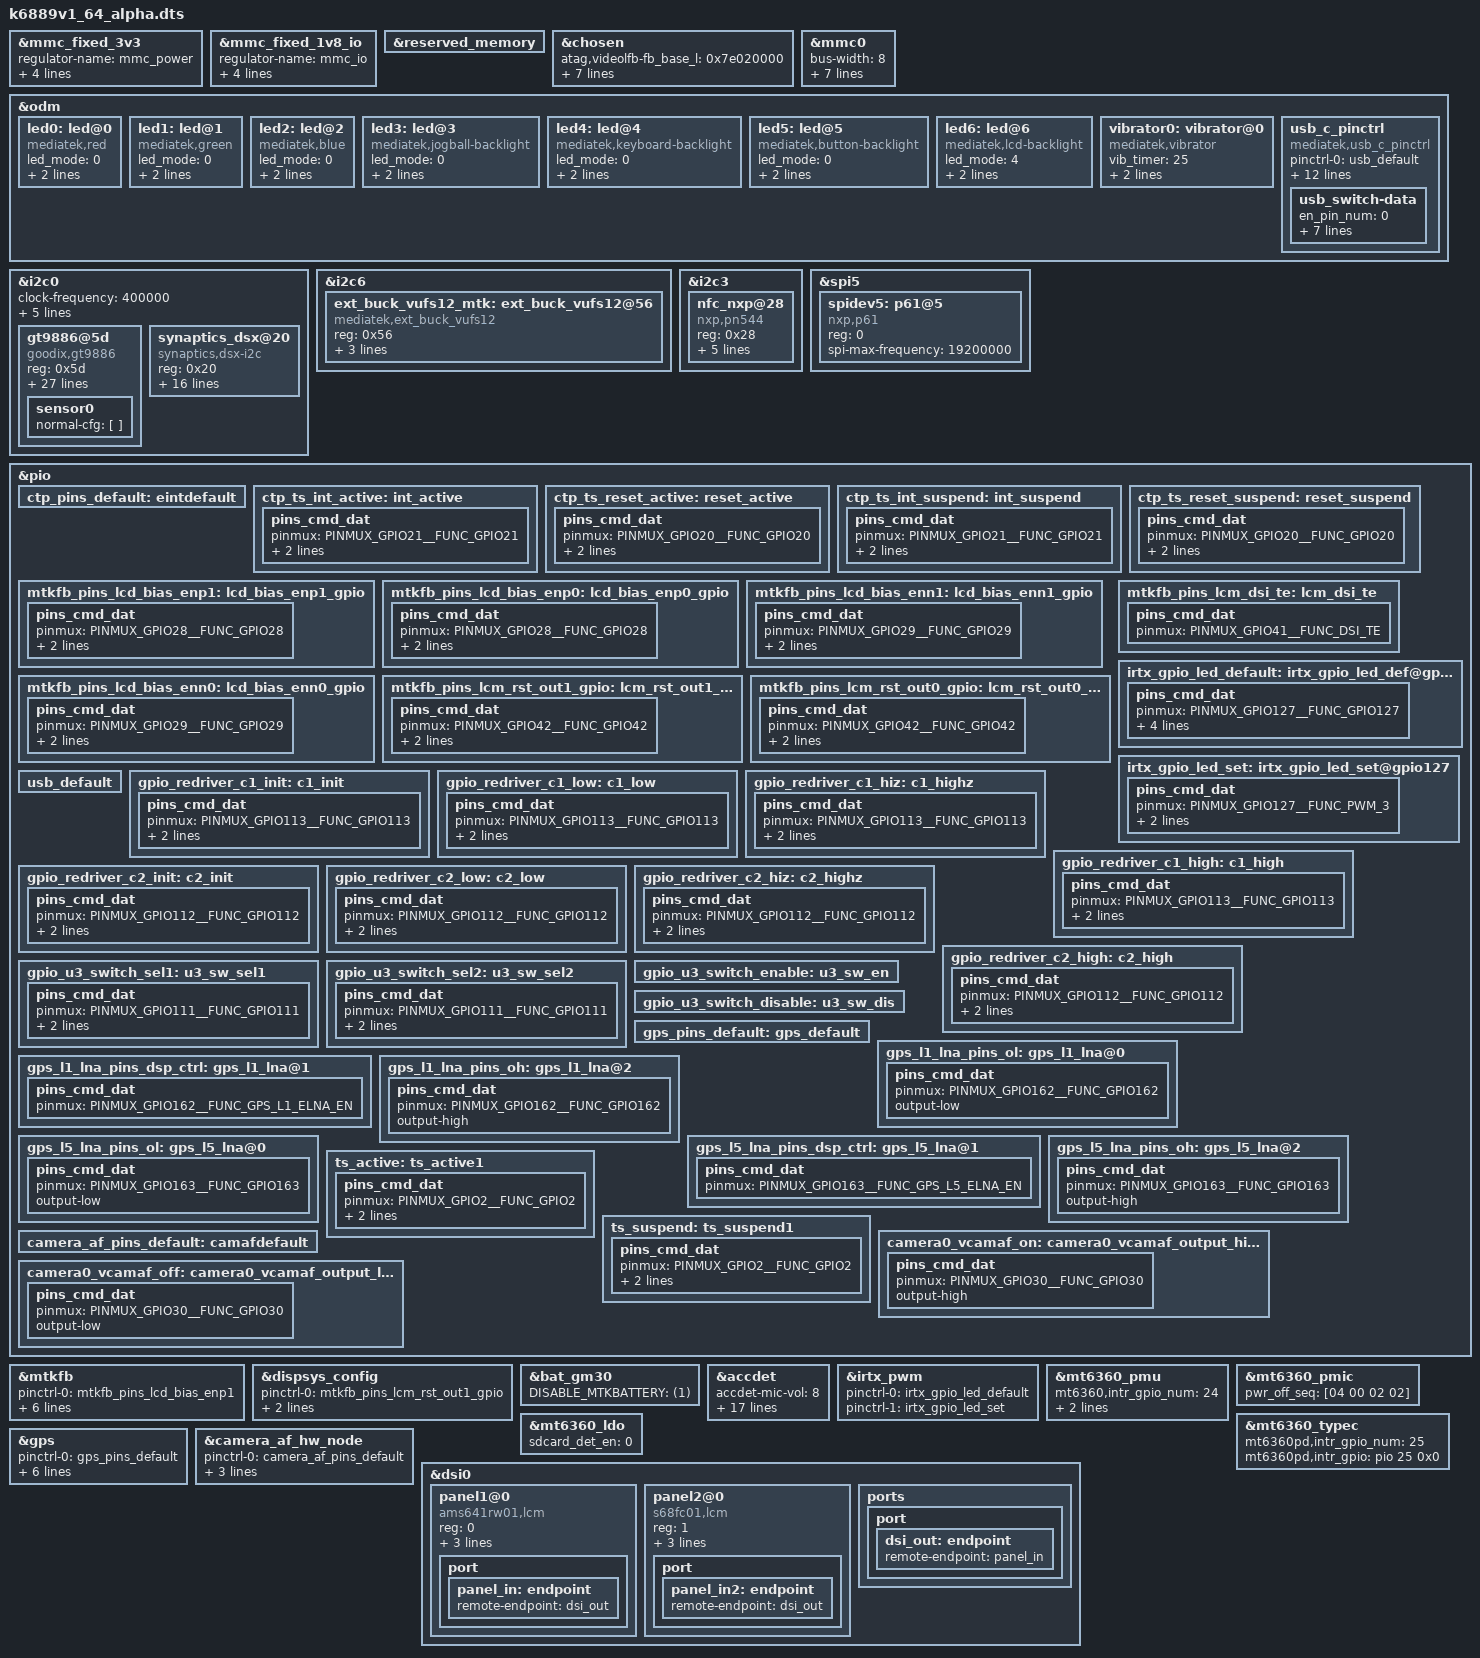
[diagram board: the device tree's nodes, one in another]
/*
 * Mediatek's mt6885 SoC device tree source
 *
 * Copyright (C) 2016 MediaTek Inc.
 *
 * This program is free software; you can redistribute it and/or modify
 * it under the terms of the GNU General Public License version 2 as
 * published by the Free Software Foundation.
 *
 * This program is distributed in the hope that it will be useful,
 * but WITHOUT ANY WARRANTY; without even the implied warranty of
 * MERCHANTABILITY or FITNESS FOR A PARTICULAR PURPOSE.
 * See http://www.gnu.org/licenses/gpl-2.0.html for more details.
 */
/dts-v1/;
/plugin/;
#include <dt-bindings/interrupt-controller/irq.h>
#include <dt-bindings/interrupt-controller/arm-gic.h>
#include <dt-bindings/spmi/spmi.h>
#include <dt-bindings/pinctrl/mt6885-pinfunc.h>

&mmc_fixed_3v3 {
	status = "okay";
	regulator-name = "mmc_power";
	regulator-min-microvolt = <3300000>;
	regulator-max-microvolt = <3300000>;
	enable-active-high;
	regulator-always-on;
};

&mmc_fixed_1v8_io {
	status = "okay";
	regulator-name = "mmc_io";
	regulator-min-microvolt = <1800000>;
	regulator-max-microvolt = <1800000>;
	enable-active-high;
	regulator-always-on;
};

&reserved_memory {
};

/* chosen */
&chosen {

	atag,videolfb-fb_base_l = <0x7e020000>;
	atag,videolfb-fb_base_h = <0x0>;
	atag,videolfb-islcmfound = <1>;
	atag,videolfb-islcm_inited = <0>;
	atag,videolfb-fps= <6000>;
	atag,videolfb-vramSize= <0x1be0000>;
	atag,videolfb-lcmname=
		"nt35595_fhd_dsi_cmd_truly_nt50358_drv";
};

&mmc0 {
	status = "okay";
	/* pinctrl-names = "default", "state_uhs"; */
	/* pinctrl-0 = <&mmc0_pins_default>; */
	/* pinctrl-1 = <&mmc0_pins_uhs>; */
	bus-width = <8>;
	max-frequency = <5000000>;
	cap-mmc-highspeed;
	no-sdio;
	no-sd;
	vmmc-supply = <&mmc_fixed_3v3>;
	vqmmc-supply = <&mmc_fixed_1v8_io>;
	non-removable;
};

&odm {
	led0:led@0 {
		compatible = "mediatek,red";
		led_mode = <0>;
		data = <1>;
		pwm_config = <0 0 0 0 0>;
	};
	led1:led@1 {
		compatible = "mediatek,green";
		led_mode = <0>;
		data = <1>;
		pwm_config = <0 0 0 0 0>;
	};
	led2:led@2 {
		compatible = "mediatek,blue";
		led_mode = <0>;
		data = <1>;
		pwm_config = <0 0 0 0 0>;
	};
	led3:led@3 {
		compatible = "mediatek,jogball-backlight";
		led_mode = <0>;
		data = <1>;
		pwm_config = <0 0 0 0 0>;
	};
	led4:led@4 {
		compatible = "mediatek,keyboard-backlight";
		led_mode = <0>;
		data = <1>;
		pwm_config = <0 0 0 0 0>;
	};
	led5:led@5 {
		compatible = "mediatek,button-backlight";
		led_mode = <0>;
		data = <1>;
		pwm_config = <0 0 0 0 0>;
	};
	led6:led@6 {
		compatible = "mediatek,lcd-backlight";
		led_mode = <4>;
		data = <1>;
		pwm_config = <0 1 0 0 0>;
	};
	vibrator0:vibrator@0 {
		compatible = "mediatek,vibrator";
		vib_timer = <25>;
		vib_limit = <9>;
		vib_vol= <9>;
	};
	usb_c_pinctrl:usb_c_pinctrl {
		compatible = "mediatek,usb_c_pinctrl";
	};
};

/* TOUCH start */
&i2c0 {
	clock-frequency = <400000>;
	pinctrl-names = "default", "ts_int_active",
		"ts_reset_active", "ts_int_suspend", "ts_reset_suspend";
	pinctrl-0 = <&ctp_pins_default>;
	pinctrl-1 = <&ctp_ts_int_active>;
	pinctrl-2 = <&ctp_ts_reset_active>;
	pinctrl-3 = <&ctp_ts_int_suspend>;
	pinctrl-4 = <&ctp_ts_reset_suspend>;

	gt9886@5d {
		compatible = "goodix,gt9886";
		reg = <0x5d>;
		status = "ok";
		interrupt-parent = <&pio>;
		interrupts = <21 IRQ_TYPE_EDGE_FALLING 21 0>;
		vtouch-supply = <&mt_pmic_vtp_ldo_reg>;
		goodix,reset-gpio = <&pio 20 0x0>;
		goodix,irq-gpio = <&pio 21 0x0>;
		goodix,irq-flags = <2>; /* 1:rising, 2:falling;*/
		goodix,panel-max-id = <10>;
		goodix,panel-max-x = <1080>;
		goodix,panel-max-y = <2400>;
		goodix,panel-max-w = <256>;
		goodix,panel-max-p = <256>;
		goodix,input-max-x = <1080>;
		goodix,input-max-y = <2400>;
		goodix,panel-key-map = <158 172 217>; /*BACK,HOMEPAGE,SEARCH*/
		goodix,power-on-delay-us = <10000>; /*10ms*/
		goodix,power-off-delay-us = <5000>;
		goodix,firmware-version = "6885b0";
		goodix,config-version = "gt9885v1";
		/*goodix,swap-axis;*/
		goodix,x2x;
		goodix,y2y;
		goodix,pen-enable;
		goodix,key-of-pen = <331 332>;/*BTN_STYLUS, BTN_STYLUS2*/
		tpd-filter-enable = <0>;
		tpd-filter-pixel-density = <168>;
		tpd-filter-custom-prameters = <0 0 0 0 0 0 0 0 0 0 0 0>;
		tpd-filter-custom-speed = <0 0 0>;
		sensor0 {
			normal-cfg = [
			];
		};
	};

};

&i2c6 {
	ext_buck_vufs12_mtk:ext_buck_vufs12@56 {
		compatible = "mediatek,ext_buck_vufs12";
		reg = <0x56>;
		regulator-name = "ext_buck_vufs12";
		regulator-min-microvolt = <300000>;
		regulator-max-microvolt = <1300000>;
		status = "okay";
	};
};
&i2c3 {
       status = "okay";
       nfc_nxp@28 {
               compatible = "nxp,pn544";
               reg = <0x28>;
               nxp,pn544-irq = <&pio 7 0x0>;
               nxp,pn544-ven = <&pio 16 0x0>;
               nxp,pn544-fw-dwnld = <&pio 6 0x0>;
               nxp,pn544-clkreq = <&pio 17 0x0>;
               interrupt-parent = <&pio>;
       };
};

&spi5 {
       status = "okay";
       #address-cells = <1>;
       #size-cells = <0>;
       spidev5: p61@5 {
       compatible = "nxp,p61";
       reg = <0>;
       spi-max-frequency = <19200000>;
       };
};

&pio {
	ctp_pins_default: eintdefault {
	};
	ctp_ts_int_active: int_active {
		pins_cmd_dat {
			pinmux = <PINMUX_GPIO21__FUNC_GPIO21>;
			slew-rate = <0>;
			bias-pull-up = <11>;
		};
	};
	ctp_ts_reset_active: reset_active {
		pins_cmd_dat {
			pinmux = <PINMUX_GPIO20__FUNC_GPIO20>;
			slew-rate = <1>;
			output-high;
		};
	};
	ctp_ts_int_suspend: int_suspend {
		pins_cmd_dat {
			pinmux = <PINMUX_GPIO21__FUNC_GPIO21>;
			slew-rate = <1>;
			output-low;
		};
	};
	ctp_ts_reset_suspend: reset_suspend {
		pins_cmd_dat {
			pinmux = <PINMUX_GPIO20__FUNC_GPIO20>;
			slew-rate = <1>;
			output-low;
		};
	};
};
/* TOUCH end */

/* DISPSYS GPIO standardization */
&pio {
	mtkfb_pins_lcd_bias_enp1: lcd_bias_enp1_gpio {
		pins_cmd_dat {
			pinmux = <PINMUX_GPIO28__FUNC_GPIO28>;
			slew-rate = <1>;
			output-high;
		};
	};

	mtkfb_pins_lcd_bias_enp0: lcd_bias_enp0_gpio {
		pins_cmd_dat {
			pinmux = <PINMUX_GPIO28__FUNC_GPIO28>;
			slew-rate = <1>;
			output-low;
		};
	};

	mtkfb_pins_lcd_bias_enn1: lcd_bias_enn1_gpio {
		pins_cmd_dat {
			pinmux = <PINMUX_GPIO29__FUNC_GPIO29>;
			slew-rate = <1>;
			output-high;
		};
	};

	mtkfb_pins_lcd_bias_enn0: lcd_bias_enn0_gpio {
		pins_cmd_dat {
			pinmux = <PINMUX_GPIO29__FUNC_GPIO29>;
			slew-rate = <1>;
			output-low;
		};
	};

	mtkfb_pins_lcm_rst_out1_gpio: lcm_rst_out1_gpio {
		pins_cmd_dat {
			pinmux = <PINMUX_GPIO42__FUNC_GPIO42>;
			slew-rate = <1>;
			output-high;
		};
	};

	mtkfb_pins_lcm_rst_out0_gpio: lcm_rst_out0_gpio {
		pins_cmd_dat {
			pinmux = <PINMUX_GPIO42__FUNC_GPIO42>;
			slew-rate = <1>;
			output-low;
		};
	};

	mtkfb_pins_lcm_dsi_te: lcm_dsi_te {
		pins_cmd_dat {
			pinmux = <PINMUX_GPIO41__FUNC_DSI_TE>;
		};
	};
};

&mtkfb {
	pinctrl-names = "lcd_bias_enp1_gpio", "lcd_bias_enp0_gpio",
		"lcd_bias_enn1_gpio", "lcd_bias_enn0_gpio",
		"lcm_rst_out1_gpio", "lcm_rst_out0_gpio",
		"mode_te_te";
	pinctrl-0 = <&mtkfb_pins_lcd_bias_enp1>;
	pinctrl-1 = <&mtkfb_pins_lcd_bias_enp0>;
	pinctrl-2 = <&mtkfb_pins_lcd_bias_enn1>;
	pinctrl-3 = <&mtkfb_pins_lcd_bias_enn0>;
	pinctrl-4 = <&mtkfb_pins_lcm_rst_out1_gpio>;
	pinctrl-5 = <&mtkfb_pins_lcm_rst_out0_gpio>;
	pinctrl-6 = <&mtkfb_pins_lcm_dsi_te>;
	status = "okay";
};

&dispsys_config {
	pinctrl-names =
		"lcm_rst_out1_gpio", "lcm_rst_out0_gpio",
		"mode_te_te";
	pinctrl-0 = <&mtkfb_pins_lcm_rst_out1_gpio>;
	pinctrl-1 = <&mtkfb_pins_lcm_rst_out0_gpio>;
	pinctrl-2 = <&mtkfb_pins_lcm_dsi_te>;
	status = "okay";
};

&bat_gm30 {
	DISABLE_MTKBATTERY = <(1)>;
};

/* DISPSYS GPIO standardization end */

/* accdet start */
&accdet {
	/* accdet micbias voltage: 0x09:2.85v 0x08:2.8v 0x07,
	 * 2.7v;0x05,2.5v;0x02,1.9v
	 */
	accdet-mic-vol = <8>;
	/* accdet pwm_width, pwm_thresh, fall_delay, rise_delay
	 * debounce0, debounce1, debounce3, debounce4
	 * eint pwm_width, eint pwm_thresh
	 * eint deb(debounce0, debounce1, debounce2, debounce3), inv_debounce
	 */
	headset-mode-setting = <0x500 0x500 1 0x1f0
				0x2000 0x800 0x2000 0x44
				0x0 0x7
				0x5 0x9 0x9 0xd 0xe>;
	accdet-plugout-debounce = <1>;
	/*1:ACC mode, 2:low cost without in bias, 6:low cost with in bias*/
	accdet-mic-mode = <2>;
	/*0--MD_MAX--UP_MAX--DW_MAX*/
	headset-three-key-threshold = <0 80 220 400>;
	headset-three-key-threshold-CDD = <0 121 192 600>;
	/*0--MD_MAX--VOICE_MAX--UP_MAX--DW_MAX*/
	headset-four-key-threshold = <0 58 121 192 400>;

	/* moisture HW mode config start. Enable moisture detection or not
	 * default use HW mode for moisture detection
	 */
	moisture_detect_enable = <1>;
	/* select VTH to 2v and 500k, use internal resitance */
	eint_use_ext_res = <0>;
	/* enable eint detection mode, if moisture detection enable
	 * eint_detect_mode = moisture_detect_mode;otherwise, select
	 * eint_detect_mode = 4 as DEFAULT
	 */
	eint_detect_mode = <5>;
	/* enable moisture detection mode, if moisture detection enable
	 * eint_detect_mode = moisture_detect_mode
	 */
	moisture_detect_mode = <5>;
	/* select 0: 2.8V; 1: 2.4V; 2: 2V; 3: VTH=MVTH(VTH2) */
	moisture_comp_vth = <2>;
	/* vref2 voltage for different water impedance */
	moisture_comp_vref2 = <0>;
	/* moisture HW mode config end */

	/* moisture SW mode config start, use external resister or not.
	 * DEFAULT NOT NEED
	 */
	moisture_use_ext_res = <0>;
	/* moisture external resister ohm, SW mode by auxadc */
	moisture-external-r = <2000000>;
	/* moisture internal resister ohm, SW mode by auxadc */
	moisture-internal-r = <47000>;
	/* moisture of water resister ohm, SW mode by auxadc*/
	moisture-water-r = <10000>;
	/* moisture SW mode config end */
	status = "okay";
};
/* accdet end */

/* IRTX GPIO Start */
&irtx_pwm {
	pinctrl-names = "irtx_gpio_led_default", "irtx_gpio_led_set";
	pinctrl-0 = <&irtx_gpio_led_default>;
	pinctrl-1 = <&irtx_gpio_led_set>;
	status = "okay";
};
&pio {
	/* IRTX GPIO Settings -Start */
	/* default: GPIO0, output, high */
	irtx_gpio_led_default:irtx_gpio_led_def@gpio127 {
		pins_cmd_dat {
			pinmux = <PINMUX_GPIO127__FUNC_GPIO127>;
			slew-rate = <1>;
			bias-disable;
			output-low;
			input-schmitt-enable = <0>;
		};
	};

	irtx_gpio_led_set:irtx_gpio_led_set@gpio127 {
		pins_cmd_dat {
			pinmux = <PINMUX_GPIO127__FUNC_PWM_3>;
			slew-rate = <1>;
			output-high;
		};
	};
}; /* IRTX GPIO Settings -End */

&mt6360_pmu {
	mt6360,intr_gpio_num = <24>; /* direct defined GPIO num */
	mt6360,intr_gpio = <&pio 24 0x0>;
	disable_lpsd = <1>;
};

&mt6360_pmic {
	pwr_off_seq = [04 00 02 02];
};

&mt6360_typec {
	mt6360pd,intr_gpio_num = <25>; /* direct defined GPIO num */
	mt6360pd,intr_gpio = <&pio 25 0x0>;
};

&mt6360_ldo {
	sdcard_det_en = <0>;
};

/* USB SWITCH GPIO start */
&pio {
	usb_default: usb_default {
	};

	gpio_redriver_c1_init: c1_init {
		pins_cmd_dat {
			pinmux = <PINMUX_GPIO113__FUNC_GPIO113>;
			slew-rate = <1>;
			output-low;
		};
	};

	gpio_redriver_c1_low: c1_low {
		pins_cmd_dat {
			pinmux = <PINMUX_GPIO113__FUNC_GPIO113>;
			slew-rate = <1>;
			output-low;
		};
	};

	gpio_redriver_c1_hiz: c1_highz {
		pins_cmd_dat {
			pinmux = <PINMUX_GPIO113__FUNC_GPIO113>;
			slew-rate= <0>;
			bias-disable;
		};
	};

	gpio_redriver_c1_high: c1_high {
		pins_cmd_dat {
			pinmux = <PINMUX_GPIO113__FUNC_GPIO113>;
			slew-rate = <1>;
			output-high;
		};
	};

	gpio_redriver_c2_init: c2_init {
		pins_cmd_dat {
			pinmux = <PINMUX_GPIO112__FUNC_GPIO112>;
			slew-rate = <1>;
			output-low;
		};
	};

	gpio_redriver_c2_low: c2_low {
		pins_cmd_dat {
			pinmux = <PINMUX_GPIO112__FUNC_GPIO112>;
			slew-rate = <1>;
			output-low;
		};
	};

	gpio_redriver_c2_hiz: c2_highz {
		pins_cmd_dat {
			pinmux = <PINMUX_GPIO112__FUNC_GPIO112>;
			slew-rate= <0>;
			bias-disable;
		};
	};

	gpio_redriver_c2_high: c2_high {
		pins_cmd_dat {
			pinmux = <PINMUX_GPIO112__FUNC_GPIO112>;
			slew-rate = <1>;
			output-high;
		};
	};

	gpio_u3_switch_sel1: u3_sw_sel1 {
		pins_cmd_dat {
			pinmux = <PINMUX_GPIO111__FUNC_GPIO111>;
			slew-rate = <1>;
			output-low;
		};
	};

	gpio_u3_switch_sel2: u3_sw_sel2 {
		pins_cmd_dat {
			pinmux = <PINMUX_GPIO111__FUNC_GPIO111>;
			slew-rate = <1>;
			output-high;
		};
	};

	gpio_u3_switch_enable: u3_sw_en {
	};

	gpio_u3_switch_disable: u3_sw_dis {
	};
};

&usb_c_pinctrl {
	pinctrl-names = "usb_default",
		"redrv_c1_init",
		"redrv_c1_low",
		"redrv_c1_hiz",
		"redrv_c1_high",
		"redrv_c2_init",
		"redrv_c2_low",
		"redrv_c2_hiz",
		"redrv_c2_high",
		"switch_sel1",
		"switch_sel2",
		"switch_enable",
		"switch_disable";

	pinctrl-0 = <&usb_default>;
	pinctrl-1 = <&gpio_redriver_c1_init>;
	pinctrl-2 = <&gpio_redriver_c1_low>;
	pinctrl-3 = <&gpio_redriver_c1_hiz>;
	pinctrl-4 = <&gpio_redriver_c1_high>;
	pinctrl-5 = <&gpio_redriver_c2_init>;
	pinctrl-6 = <&gpio_redriver_c2_low>;
	pinctrl-7 = <&gpio_redriver_c2_hiz>;
	pinctrl-8 = <&gpio_redriver_c2_high>;
	pinctrl-9 = <&gpio_u3_switch_sel1>;
	pinctrl-10 = <&gpio_u3_switch_sel2>;
	pinctrl-11 = <&gpio_u3_switch_enable>;
	pinctrl-12 = <&gpio_u3_switch_disable>;
	status = "okay";

	usb_switch-data {
		en_pin_num = <0>;
		en_pin_val = <0>;
		sel_pin_num = <111>;
		sel_pin_val = <1>;
		c1_pin_num = <113>;
		c1_pin_val = <2>;
		c2_pin_num = <112>;
		c2_pin_val = <1>;
	};
};
/* USB SWITCH GPIO end */

/* GPS GPIO standardization start */
&pio {
	gps_pins_default: gps_default {
	};

	gps_l1_lna_pins_ol: gps_l1_lna@0 {
		pins_cmd_dat {
			pinmux = <PINMUX_GPIO162__FUNC_GPIO162>;
			output-low;
		};
	};
	gps_l1_lna_pins_dsp_ctrl: gps_l1_lna@1 {
		pins_cmd_dat {
			pinmux = <PINMUX_GPIO162__FUNC_GPS_L1_ELNA_EN>;
		};
	};
	gps_l1_lna_pins_oh: gps_l1_lna@2 {
		pins_cmd_dat {
			pinmux = <PINMUX_GPIO162__FUNC_GPIO162>;
			output-high;
		};
	};

	gps_l5_lna_pins_ol: gps_l5_lna@0 {
		pins_cmd_dat {
			pinmux = <PINMUX_GPIO163__FUNC_GPIO163>;
			output-low;
		};
	};
	gps_l5_lna_pins_dsp_ctrl: gps_l5_lna@1 {
		pins_cmd_dat {
			pinmux = <PINMUX_GPIO163__FUNC_GPS_L5_ELNA_EN>;
		};
	};
	gps_l5_lna_pins_oh: gps_l5_lna@2 {
		pins_cmd_dat {
			pinmux = <PINMUX_GPIO163__FUNC_GPIO163>;
			output-high;
		};
	};
};

&gps {
	pinctrl-names = "default",
		"gps_l1_lna_disable",
		"gps_l1_lna_dsp_ctrl",
		"gps_l1_lna_enable",
		"gps_l5_lna_disable",
		"gps_l5_lna_dsp_ctrl",
		"gps_l5_lna_enable";
	pinctrl-0 = <&gps_pins_default>;
	pinctrl-1 = <&gps_l1_lna_pins_ol>;
	pinctrl-2 = <&gps_l1_lna_pins_dsp_ctrl>;
	pinctrl-3 = <&gps_l1_lna_pins_oh>;
	pinctrl-4 = <&gps_l5_lna_pins_ol>;
	pinctrl-5 = <&gps_l5_lna_pins_dsp_ctrl>;
	pinctrl-6 = <&gps_l5_lna_pins_oh>;
	status = "okay";
};
/* GPS GPIO standardization end */

&i2c0 {
	status = "ok";
	synaptics_dsx@20 {
		compatible = "synaptics,dsx-i2c";
		reg = <0x20>;
		interrupt-parent = <&pio>;
		interrupts = <1 0x2008>;
		vdd-supply = <&mt_pmic_vtp_ldo_reg>;
		avdd-supply = <&mt_pmic_vtp_ldo_reg>;
		pinctrl-names = "pmx_ts_active", "pmx_ts_suspend";
		pinctrl-0 = <&ts_active>;
		pinctrl-1 = <&ts_suspend>;
		synaptics,pwr-reg-name = "avdd";
		synaptics,bus-reg-name = "vdd";
		synaptics,ub-i2c-addr = <0x2c>;
		synaptics,reset-gpio = <&pio 20 0>;
		synaptics,irq-gpio = <&pio 21 0x2008>; /* IRQF_ONESHOT | IRQF_TRIGGER_LOW */
		synaptics,irq-on-state = <0>;
		synaptics,power-delay-ms = <8>;
		synaptics,reset-delay-ms = <90>;
		synaptics,reset-on-state = <0>;
		synaptics,reset-active-ms = <2>;
		/* uncomment and update line below as appropriate if there are 0D buttons */
		/* synaptics,cap-button-codes = <102 158>; */
		/* uncomment and update lines below as appropriate if there are virtual buttons */
		/* synaptics,vir-button-codes = <102 100 900 100 60 158 300 900 100 60>; */
		/* synaptics,max-y-for-2d = <800>; */
	};
};

&pio {
	ts_active: ts_active1 {
		pins_cmd_dat {
			pinmux = <PINMUX_GPIO2__FUNC_GPIO2>;
			slew-rate = <1>;
			output-high;
		};
	};
	ts_suspend: ts_suspend1 {
		pins_cmd_dat {
			pinmux = <PINMUX_GPIO2__FUNC_GPIO2>;
			slew-rate = <1>;
			output-low;
		};
	};
};


&pio {
	camera_af_pins_default: camafdefault {
	};
	camera0_vcamaf_on: camera0_vcamaf_output_high@gpio30 {
		pins_cmd_dat {
			pinmux = <PINMUX_GPIO30__FUNC_GPIO30>;
			output-high;
		};
	};
	camera0_vcamaf_off: camera0_vcamaf_output_low@gpio30 {
		pins_cmd_dat {
			pinmux = <PINMUX_GPIO30__FUNC_GPIO30>;
			output-low;
		};
	};
};

&camera_af_hw_node {
	pinctrl-names = "default",
			"cam0_ldo_vcamaf_0", "cam0_ldo_vcamaf_1";
	pinctrl-0 = <&camera_af_pins_default>;
	pinctrl-1 = <&camera0_vcamaf_off>;
	pinctrl-2 = <&camera0_vcamaf_on>;
	vcamaf-supply = <&mt_pmic_vmc_ldo_reg>;
	status = "okay";
};

&dsi0 {
	status = "okay";
	#address-cells = <1>;
	#size-cells = <0>;
	panel1@0 {
		compatible = "ams641rw01,lcm";
		reg = <0>;
		pm-enable-gpios = <&pio 41 0>;
		reset-gpios = <&pio 42 0>;
		bias-gpio = <&pio 29 0>;
		pinctrl-names = "default";
		port {
			panel_in: endpoint {
				remote-endpoint = <&dsi_out>;
			};
		};
	};
	panel2@0 {
		compatible = "s68fc01,lcm";
		reg = <1>;
		pm-enable-gpios = <&pio 41 0>;
		reset-gpios = <&pio 42 0>;
		bias-gpio = <&pio 29 0>;
		pinctrl-names = "default";
		port {
			panel_in2: endpoint {
				remote-endpoint = <&dsi_out>;
			};
		};
	};
	ports {
		port {
			dsi_out: endpoint {
				remote-endpoint = <&panel_in>;
			};
		};
	};
};

#include "cust_mt6885_alpha_camera.dtsi"
#include <k6889v1_64_alpha/cust.dtsi>
/*End of this file, DO NOT ADD ANYTHING HERE*/
